# ESP32-P4 register map
Vendor: ESPRESSIF SYSTEMS (SHANGHAI) CO., LTD.; Series: ESP32 P-Series; File version: 2
CPU: RV32IMAFC r0p0, little endian, no MPU, FPU, 0 interrupt priority bits
Address unit: 32 bits
Registers are 32-bit, read-write, reset 0x0 unless marked. A register's access mark holds for its fields unless they carry their own. Offsets are from the block's base; [hi:lo] are bit positions; {n}, {i} and the like mark numbered series.

## DMA — DMA (Direct Memory Access) Controller
Base 0x50081000
0x00 ID0 ro
  [31:0] DMAC_ID
0x08 COMPVER0 ro reset 0x3230302A
  [31:0] DMAC_COMPVER
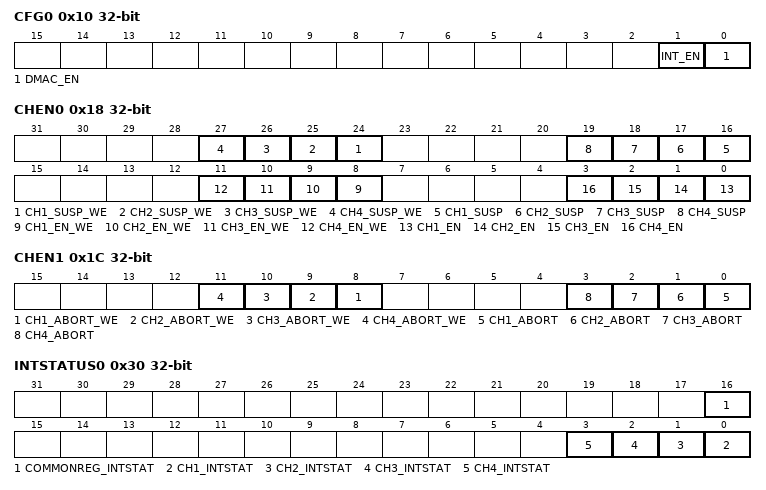
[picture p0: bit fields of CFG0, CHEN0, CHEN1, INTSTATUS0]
0x10 CFG0
  [1] INT_EN, [0] DMAC_EN
0x18 CHEN0 access per field
  [n+23] CH{n}_SUSP_WE wo (n=1..4), [n+15] CH{n}_SUSP rw (n=1..4), [n+7] CH{n}_EN_WE wo (n=1..4), [n-1] CH{n}_EN rw (n=1..4)
0x1C CHEN1 access per field
  [n+7] CH{n}_ABORT_WE wo (n=1..4), [n-1] CH{n}_ABORT rw (n=1..4)
0x30 INTSTATUS0 ro
  [16] COMMONREG_INTSTAT, [n-1] CH{n}_INTSTAT (n=1..4)
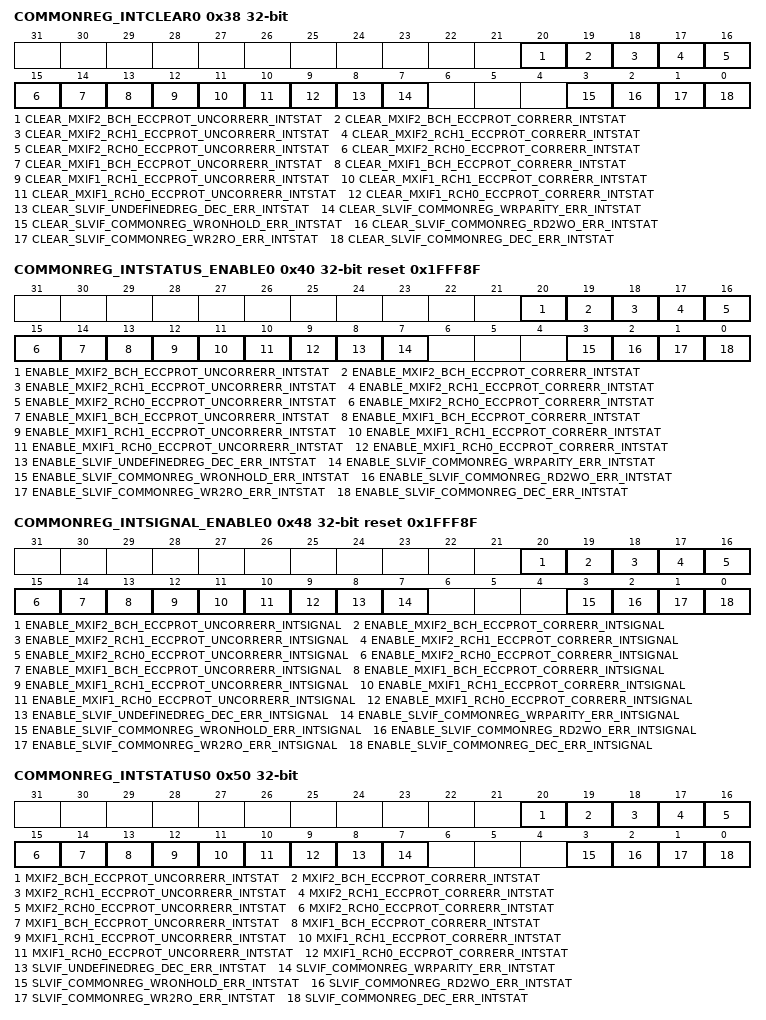
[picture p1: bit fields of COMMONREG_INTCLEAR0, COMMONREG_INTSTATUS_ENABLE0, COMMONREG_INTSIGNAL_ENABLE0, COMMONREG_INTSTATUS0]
0x38 COMMONREG_INTCLEAR0 wo
  [20] CLEAR_MXIF2_BCH_ECCPROT_UNCORRERR_INTSTAT, [19] CLEAR_MXIF2_BCH_ECCPROT_CORRERR_INTSTAT, [18] CLEAR_MXIF2_RCH1_ECCPROT_UNCORRERR_INTSTAT, [17] CLEAR_MXIF2_RCH1_ECCPROT_CORRERR_INTSTAT, [16] CLEAR_MXIF2_RCH0_ECCPROT_UNCORRERR_INTSTAT, [15] CLEAR_MXIF2_RCH0_ECCPROT_CORRERR_INTSTAT, [14] CLEAR_MXIF1_BCH_ECCPROT_UNCORRERR_INTSTAT, [13] CLEAR_MXIF1_BCH_ECCPROT_CORRERR_INTSTAT, [12] CLEAR_MXIF1_RCH1_ECCPROT_UNCORRERR_INTSTAT, [11] CLEAR_MXIF1_RCH1_ECCPROT_CORRERR_INTSTAT, [10] CLEAR_MXIF1_RCH0_ECCPROT_UNCORRERR_INTSTAT, [9] CLEAR_MXIF1_RCH0_ECCPROT_CORRERR_INTSTAT, [8] CLEAR_SLVIF_UNDEFINEDREG_DEC_ERR_INTSTAT, [7] CLEAR_SLVIF_COMMONREG_WRPARITY_ERR_INTSTAT, [3] CLEAR_SLVIF_COMMONREG_WRONHOLD_ERR_INTSTAT, [2] CLEAR_SLVIF_COMMONREG_RD2WO_ERR_INTSTAT, [1] CLEAR_SLVIF_COMMONREG_WR2RO_ERR_INTSTAT, [0] CLEAR_SLVIF_COMMONREG_DEC_ERR_INTSTAT
0x40 COMMONREG_INTSTATUS_ENABLE0 access per field reset 0x1FFF8F
  [20] ENABLE_MXIF2_BCH_ECCPROT_UNCORRERR_INTSTAT ro, [19] ENABLE_MXIF2_BCH_ECCPROT_CORRERR_INTSTAT ro, [18] ENABLE_MXIF2_RCH1_ECCPROT_UNCORRERR_INTSTAT ro, [17] ENABLE_MXIF2_RCH1_ECCPROT_CORRERR_INTSTAT ro, [16] ENABLE_MXIF2_RCH0_ECCPROT_UNCORRERR_INTSTAT ro, [15] ENABLE_MXIF2_RCH0_ECCPROT_CORRERR_INTSTAT ro, [14] ENABLE_MXIF1_BCH_ECCPROT_UNCORRERR_INTSTAT ro, [13] ENABLE_MXIF1_BCH_ECCPROT_CORRERR_INTSTAT ro, [12] ENABLE_MXIF1_RCH1_ECCPROT_UNCORRERR_INTSTAT ro, [11] ENABLE_MXIF1_RCH1_ECCPROT_CORRERR_INTSTAT ro, [10] ENABLE_MXIF1_RCH0_ECCPROT_UNCORRERR_INTSTAT ro, [9] ENABLE_MXIF1_RCH0_ECCPROT_CORRERR_INTSTAT ro, [8] ENABLE_SLVIF_UNDEFINEDREG_DEC_ERR_INTSTAT rw, [7] ENABLE_SLVIF_COMMONREG_WRPARITY_ERR_INTSTAT ro, [3] ENABLE_SLVIF_COMMONREG_WRONHOLD_ERR_INTSTAT rw, [2] ENABLE_SLVIF_COMMONREG_RD2WO_ERR_INTSTAT rw, [1] ENABLE_SLVIF_COMMONREG_WR2RO_ERR_INTSTAT rw, [0] ENABLE_SLVIF_COMMONREG_DEC_ERR_INTSTAT rw
0x48 COMMONREG_INTSIGNAL_ENABLE0 access per field reset 0x1FFF8F
  [20] ENABLE_MXIF2_BCH_ECCPROT_UNCORRERR_INTSIGNAL ro, [19] ENABLE_MXIF2_BCH_ECCPROT_CORRERR_INTSIGNAL ro, [18] ENABLE_MXIF2_RCH1_ECCPROT_UNCORRERR_INTSIGNAL ro, [17] ENABLE_MXIF2_RCH1_ECCPROT_CORRERR_INTSIGNAL ro, [16] ENABLE_MXIF2_RCH0_ECCPROT_UNCORRERR_INTSIGNAL ro, [15] ENABLE_MXIF2_RCH0_ECCPROT_CORRERR_INTSIGNAL ro, [14] ENABLE_MXIF1_BCH_ECCPROT_UNCORRERR_INTSIGNAL ro, [13] ENABLE_MXIF1_BCH_ECCPROT_CORRERR_INTSIGNAL ro, [12] ENABLE_MXIF1_RCH1_ECCPROT_UNCORRERR_INTSIGNAL ro, [11] ENABLE_MXIF1_RCH1_ECCPROT_CORRERR_INTSIGNAL ro, [10] ENABLE_MXIF1_RCH0_ECCPROT_UNCORRERR_INTSIGNAL ro, [9] ENABLE_MXIF1_RCH0_ECCPROT_CORRERR_INTSIGNAL ro, [8] ENABLE_SLVIF_UNDEFINEDREG_DEC_ERR_INTSIGNAL rw, [7] ENABLE_SLVIF_COMMONREG_WRPARITY_ERR_INTSIGNAL ro, [3] ENABLE_SLVIF_COMMONREG_WRONHOLD_ERR_INTSIGNAL rw, [2] ENABLE_SLVIF_COMMONREG_RD2WO_ERR_INTSIGNAL rw, [1] ENABLE_SLVIF_COMMONREG_WR2RO_ERR_INTSIGNAL rw, [0] ENABLE_SLVIF_COMMONREG_DEC_ERR_INTSIGNAL rw
0x50 COMMONREG_INTSTATUS0 ro
  [20] MXIF2_BCH_ECCPROT_UNCORRERR_INTSTAT, [19] MXIF2_BCH_ECCPROT_CORRERR_INTSTAT, [18] MXIF2_RCH1_ECCPROT_UNCORRERR_INTSTAT, [17] MXIF2_RCH1_ECCPROT_CORRERR_INTSTAT, [16] MXIF2_RCH0_ECCPROT_UNCORRERR_INTSTAT, [15] MXIF2_RCH0_ECCPROT_CORRERR_INTSTAT, [14] MXIF1_BCH_ECCPROT_UNCORRERR_INTSTAT, [13] MXIF1_BCH_ECCPROT_CORRERR_INTSTAT, [12] MXIF1_RCH1_ECCPROT_UNCORRERR_INTSTAT, [11] MXIF1_RCH1_ECCPROT_CORRERR_INTSTAT, [10] MXIF1_RCH0_ECCPROT_UNCORRERR_INTSTAT, [9] MXIF1_RCH0_ECCPROT_CORRERR_INTSTAT, [8] SLVIF_UNDEFINEDREG_DEC_ERR_INTSTAT, [7] SLVIF_COMMONREG_WRPARITY_ERR_INTSTAT, [3] SLVIF_COMMONREG_WRONHOLD_ERR_INTSTAT, [2] SLVIF_COMMONREG_RD2WO_ERR_INTSTAT, [1] SLVIF_COMMONREG_WR2RO_ERR_INTSTAT, [0] SLVIF_COMMONREG_DEC_ERR_INTSTAT
0x58 RESET0
  [0] DMAC_RST
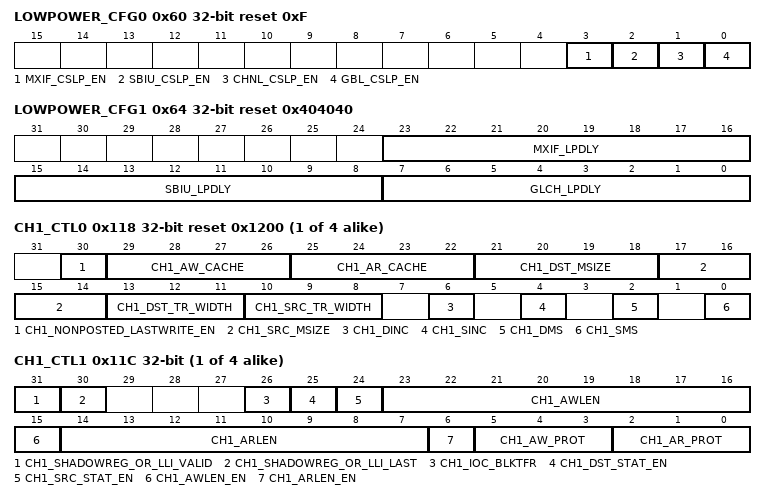
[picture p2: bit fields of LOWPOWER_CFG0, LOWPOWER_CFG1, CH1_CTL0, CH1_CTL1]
0x60 LOWPOWER_CFG0 reset 0xF
  [3] MXIF_CSLP_EN, [2] SBIU_CSLP_EN, [1] CHNL_CSLP_EN, [0] GBL_CSLP_EN
0x64 LOWPOWER_CFG1 reset 0x404040
  [23:16] MXIF_LPDLY, [15:8] SBIU_LPDLY, [7:0] GLCH_LPDLY
{0x0+0x100*i} CH{i}_SAR0 (i=1..4)
{0x4+0x100*i} CH{i}_SAR1 (i=1..4)
{0x8+0x100*i} CH{i}_DAR0 (i=1..4)
{0xC+0x100*i} CH{i}_DAR1 (i=1..4)
{0x10+0x100*i} CH{i}_BLOCK_TS0 (i=1..4)
  [21:0] CH{i}_BLOCK_TS
{0x18+0x100*i} CH{i}_CTL0 reset 0x1200 (i=1..4)
  [30] CH{i}_NONPOSTED_LASTWRITE_EN, [29:26] CH{i}_AW_CACHE, [25:22] CH{i}_AR_CACHE, [21:18] CH{i}_DST_MSIZE, [17:14] CH{i}_SRC_MSIZE, [13:11] CH{i}_DST_TR_WIDTH, [10:8] CH{i}_SRC_TR_WIDTH, [6] CH{i}_DINC, [4] CH{i}_SINC, [2] CH{i}_DMS, [0] CH{i}_SMS
{0x1C+0x100*i} CH{i}_CTL1 (i=1..4)
  [31] CH{i}_SHADOWREG_OR_LLI_VALID, [30] CH{i}_SHADOWREG_OR_LLI_LAST, [26] CH{i}_IOC_BLKTFR, [25] CH{i}_DST_STAT_EN, [24] CH{i}_SRC_STAT_EN, [23:16] CH{i}_AWLEN, [15] CH{i}_AWLEN_EN, [14:7] CH{i}_ARLEN, [6] CH{i}_ARLEN_EN, [5:3] CH{i}_AW_PROT, [2:0] CH{i}_AR_PROT
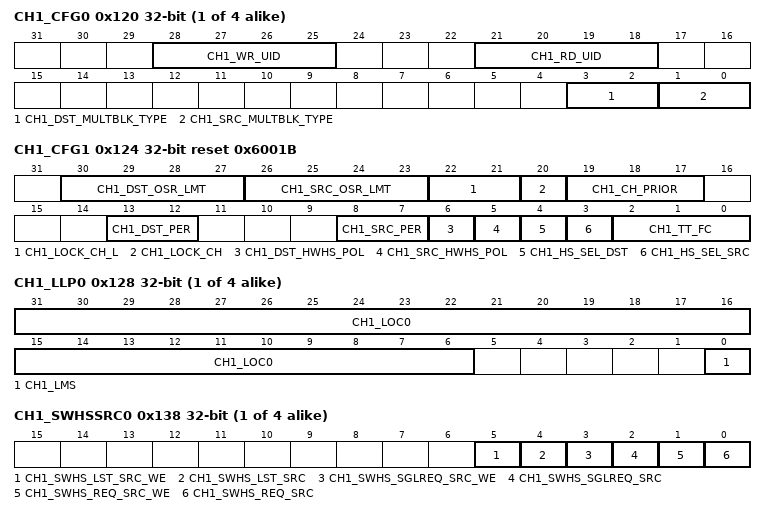
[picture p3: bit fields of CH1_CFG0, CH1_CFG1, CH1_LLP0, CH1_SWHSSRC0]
{0x20+0x100*i} CH{i}_CFG0 access per field (i=1..4)
  [28:25] CH{i}_WR_UID ro, [21:18] CH{i}_RD_UID ro, [3:2] CH{i}_DST_MULTBLK_TYPE rw, [1:0] CH{i}_SRC_MULTBLK_TYPE rw
0x124 CH1_CFG1 access per field reset 0x6001B
  [30:27] CH1_DST_OSR_LMT rw, [26:23] CH1_SRC_OSR_LMT rw, [22:21] CH1_LOCK_CH_L ro, [20] CH1_LOCK_CH ro, [19:17] CH1_CH_PRIOR rw, [13:12] CH1_DST_PER rw, [8:7] CH1_SRC_PER rw, [6] CH1_DST_HWHS_POL ro, [5] CH1_SRC_HWHS_POL ro, [4] CH1_HS_SEL_DST rw, [3] CH1_HS_SEL_SRC rw, [2:0] CH1_TT_FC rw
{0x28+0x100*i} CH{i}_LLP0 (i=1..4)
  [31:6] CH{i}_LOC0, [0] CH{i}_LMS
{0x2C+0x100*i} CH{i}_LLP1 (i=1..4)
  [31:0] CH{i}_LOC1
{0x30+0x100*i} CH{i}_STATUS0 ro (i=1..4)
  [21:0] CH{i}_CMPLTD_BLK_TFR_SIZE
{0x34+0x100*i} CH{i}_STATUS1 ro (i=1..4)
  [14:0] CH{i}_DATA_LEFT_IN_FIFO
{0x38+0x100*i} CH{i}_SWHSSRC0 access per field (i=1..4)
  [5] CH{i}_SWHS_LST_SRC_WE wo, [4] CH{i}_SWHS_LST_SRC rw, [3] CH{i}_SWHS_SGLREQ_SRC_WE wo, [2] CH{i}_SWHS_SGLREQ_SRC rw, [1] CH{i}_SWHS_REQ_SRC_WE wo, [0] CH{i}_SWHS_REQ_SRC rw
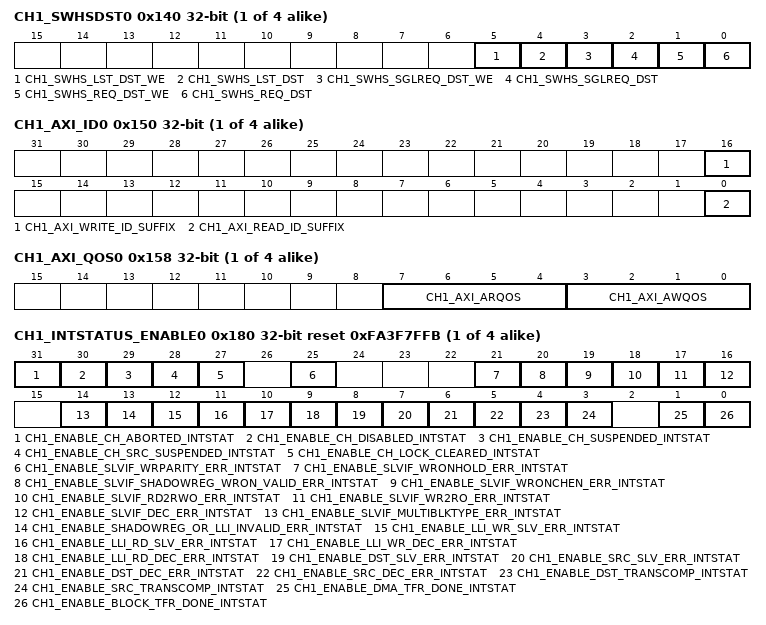
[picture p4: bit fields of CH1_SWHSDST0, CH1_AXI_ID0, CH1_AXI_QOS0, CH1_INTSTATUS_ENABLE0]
{0x40+0x100*i} CH{i}_SWHSDST0 access per field (i=1..4)
  [5] CH{i}_SWHS_LST_DST_WE wo, [4] CH{i}_SWHS_LST_DST rw, [3] CH{i}_SWHS_SGLREQ_DST_WE wo, [2] CH{i}_SWHS_SGLREQ_DST rw, [1] CH{i}_SWHS_REQ_DST_WE wo, [0] CH{i}_SWHS_REQ_DST rw
{0x48+0x100*i} CH{i}_BLK_TFR_RESUMEREQ0 wo (i=1..4)
  [0] CH{i}_BLK_TFR_RESUMEREQ
{0x50+0x100*i} CH{i}_AXI_ID0 (i=1..4)
  [16] CH{i}_AXI_WRITE_ID_SUFFIX, [0] CH{i}_AXI_READ_ID_SUFFIX
{0x58+0x100*i} CH{i}_AXI_QOS0 (i=1..4)
  [7:4] CH{i}_AXI_ARQOS, [3:0] CH{i}_AXI_AWQOS
{0x60+0x100*i} CH{i}_SSTAT0 ro (i=1..4)
  [31:0] CH{i}_SSTAT
{0x68+0x100*i} CH{i}_DSTAT0 ro (i=1..4)
  [31:0] CH{i}_DSTAT
{0x70+0x100*i} CH{i}_SSTATAR0 (i=1..4)
{0x74+0x100*i} CH{i}_SSTATAR1 (i=1..4)
{0x78+0x100*i} CH{i}_DSTATAR0 (i=1..4)
{0x7C+0x100*i} CH{i}_DSTATAR1 (i=1..4)
{0x80+0x100*i} CH{i}_INTSTATUS_ENABLE0 access per field reset 0xFA3F7FFB (i=1..4)
  [31] CH{i}_ENABLE_CH_ABORTED_INTSTAT rw, [30] CH{i}_ENABLE_CH_DISABLED_INTSTAT rw, [29] CH{i}_ENABLE_CH_SUSPENDED_INTSTAT rw, [28] CH{i}_ENABLE_CH_SRC_SUSPENDED_INTSTAT rw, [27] CH{i}_ENABLE_CH_LOCK_CLEARED_INTSTAT rw, [25] CH{i}_ENABLE_SLVIF_WRPARITY_ERR_INTSTAT ro, [21] CH{i}_ENABLE_SLVIF_WRONHOLD_ERR_INTSTAT rw, [20] CH{i}_ENABLE_SLVIF_SHADOWREG_WRON_VALID_ERR_INTSTAT rw, [19] CH{i}_ENABLE_SLVIF_WRONCHEN_ERR_INTSTAT rw, [18] CH{i}_ENABLE_SLVIF_RD2RWO_ERR_INTSTAT rw, [17] CH{i}_ENABLE_SLVIF_WR2RO_ERR_INTSTAT rw, [16] CH{i}_ENABLE_SLVIF_DEC_ERR_INTSTAT rw, [14] CH{i}_ENABLE_SLVIF_MULTIBLKTYPE_ERR_INTSTAT rw, [13] CH{i}_ENABLE_SHADOWREG_OR_LLI_INVALID_ERR_INTSTAT rw, [12] CH{i}_ENABLE_LLI_WR_SLV_ERR_INTSTAT rw, [11] CH{i}_ENABLE_LLI_RD_SLV_ERR_INTSTAT rw, [10] CH{i}_ENABLE_LLI_WR_DEC_ERR_INTSTAT rw, [9] CH{i}_ENABLE_LLI_RD_DEC_ERR_INTSTAT rw, [8] CH{i}_ENABLE_DST_SLV_ERR_INTSTAT rw, [7] CH{i}_ENABLE_SRC_SLV_ERR_INTSTAT rw, [6] CH{i}_ENABLE_DST_DEC_ERR_INTSTAT rw, [5] CH{i}_ENABLE_SRC_DEC_ERR_INTSTAT rw, [4] CH{i}_ENABLE_DST_TRANSCOMP_INTSTAT rw, [3] CH{i}_ENABLE_SRC_TRANSCOMP_INTSTAT rw, [1] CH{i}_ENABLE_DMA_TFR_DONE_INTSTAT rw, [0] CH{i}_ENABLE_BLOCK_TFR_DONE_INTSTAT rw
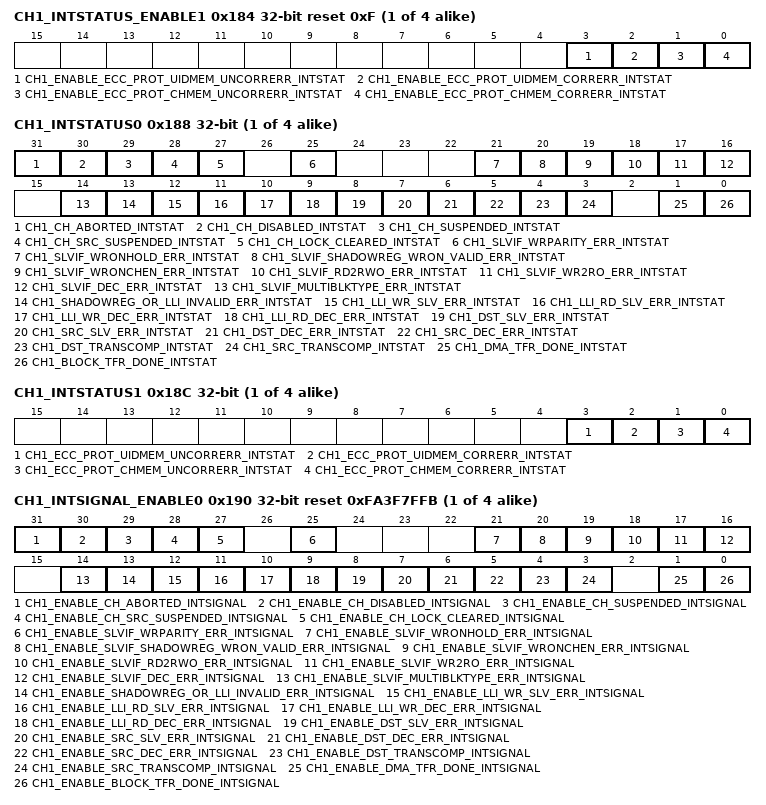
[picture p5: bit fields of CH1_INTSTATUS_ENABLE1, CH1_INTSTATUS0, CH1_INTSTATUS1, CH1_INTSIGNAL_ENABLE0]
{0x84+0x100*i} CH{i}_INTSTATUS_ENABLE1 ro reset 0xF (i=1..4)
  [3] CH{i}_ENABLE_ECC_PROT_UIDMEM_UNCORRERR_INTSTAT, [2] CH{i}_ENABLE_ECC_PROT_UIDMEM_CORRERR_INTSTAT, [1] CH{i}_ENABLE_ECC_PROT_CHMEM_UNCORRERR_INTSTAT, [0] CH{i}_ENABLE_ECC_PROT_CHMEM_CORRERR_INTSTAT
{0x88+0x100*i} CH{i}_INTSTATUS0 ro (i=1..4)
  [31] CH{i}_CH_ABORTED_INTSTAT, [30] CH{i}_CH_DISABLED_INTSTAT, [29] CH{i}_CH_SUSPENDED_INTSTAT, [28] CH{i}_CH_SRC_SUSPENDED_INTSTAT, [27] CH{i}_CH_LOCK_CLEARED_INTSTAT, [25] CH{i}_SLVIF_WRPARITY_ERR_INTSTAT, [21] CH{i}_SLVIF_WRONHOLD_ERR_INTSTAT, [20] CH{i}_SLVIF_SHADOWREG_WRON_VALID_ERR_INTSTAT, [19] CH{i}_SLVIF_WRONCHEN_ERR_INTSTAT, [18] CH{i}_SLVIF_RD2RWO_ERR_INTSTAT, [17] CH{i}_SLVIF_WR2RO_ERR_INTSTAT, [16] CH{i}_SLVIF_DEC_ERR_INTSTAT, [14] CH{i}_SLVIF_MULTIBLKTYPE_ERR_INTSTAT, [13] CH{i}_SHADOWREG_OR_LLI_INVALID_ERR_INTSTAT, [12] CH{i}_LLI_WR_SLV_ERR_INTSTAT, [11] CH{i}_LLI_RD_SLV_ERR_INTSTAT, [10] CH{i}_LLI_WR_DEC_ERR_INTSTAT, [9] CH{i}_LLI_RD_DEC_ERR_INTSTAT, [8] CH{i}_DST_SLV_ERR_INTSTAT, [7] CH{i}_SRC_SLV_ERR_INTSTAT, [6] CH{i}_DST_DEC_ERR_INTSTAT, [5] CH{i}_SRC_DEC_ERR_INTSTAT, [4] CH{i}_DST_TRANSCOMP_INTSTAT, [3] CH{i}_SRC_TRANSCOMP_INTSTAT, [1] CH{i}_DMA_TFR_DONE_INTSTAT, [0] CH{i}_BLOCK_TFR_DONE_INTSTAT
{0x8C+0x100*i} CH{i}_INTSTATUS1 ro (i=1..4)
  [3] CH{i}_ECC_PROT_UIDMEM_UNCORRERR_INTSTAT, [2] CH{i}_ECC_PROT_UIDMEM_CORRERR_INTSTAT, [1] CH{i}_ECC_PROT_CHMEM_UNCORRERR_INTSTAT, [0] CH{i}_ECC_PROT_CHMEM_CORRERR_INTSTAT
{0x90+0x100*i} CH{i}_INTSIGNAL_ENABLE0 access per field reset 0xFA3F7FFB (i=1..4)
  [31] CH{i}_ENABLE_CH_ABORTED_INTSIGNAL rw, [30] CH{i}_ENABLE_CH_DISABLED_INTSIGNAL rw, [29] CH{i}_ENABLE_CH_SUSPENDED_INTSIGNAL rw, [28] CH{i}_ENABLE_CH_SRC_SUSPENDED_INTSIGNAL rw, [27] CH{i}_ENABLE_CH_LOCK_CLEARED_INTSIGNAL rw, [25] CH{i}_ENABLE_SLVIF_WRPARITY_ERR_INTSIGNAL ro, [21] CH{i}_ENABLE_SLVIF_WRONHOLD_ERR_INTSIGNAL rw, [20] CH{i}_ENABLE_SLVIF_SHADOWREG_WRON_VALID_ERR_INTSIGNAL rw, [19] CH{i}_ENABLE_SLVIF_WRONCHEN_ERR_INTSIGNAL rw, [18] CH{i}_ENABLE_SLVIF_RD2RWO_ERR_INTSIGNAL rw, [17] CH{i}_ENABLE_SLVIF_WR2RO_ERR_INTSIGNAL rw, [16] CH{i}_ENABLE_SLVIF_DEC_ERR_INTSIGNAL rw, [14] CH{i}_ENABLE_SLVIF_MULTIBLKTYPE_ERR_INTSIGNAL rw, [13] CH{i}_ENABLE_SHADOWREG_OR_LLI_INVALID_ERR_INTSIGNAL rw, [12] CH{i}_ENABLE_LLI_WR_SLV_ERR_INTSIGNAL rw, [11] CH{i}_ENABLE_LLI_RD_SLV_ERR_INTSIGNAL rw, [10] CH{i}_ENABLE_LLI_WR_DEC_ERR_INTSIGNAL rw, [9] CH{i}_ENABLE_LLI_RD_DEC_ERR_INTSIGNAL rw, [8] CH{i}_ENABLE_DST_SLV_ERR_INTSIGNAL rw, [7] CH{i}_ENABLE_SRC_SLV_ERR_INTSIGNAL rw, [6] CH{i}_ENABLE_DST_DEC_ERR_INTSIGNAL rw, [5] CH{i}_ENABLE_SRC_DEC_ERR_INTSIGNAL rw, [4] CH{i}_ENABLE_DST_TRANSCOMP_INTSIGNAL rw, [3] CH{i}_ENABLE_SRC_TRANSCOMP_INTSIGNAL rw, [1] CH{i}_ENABLE_DMA_TFR_DONE_INTSIGNAL rw, [0] CH{i}_ENABLE_BLOCK_TFR_DONE_INTSIGNAL rw
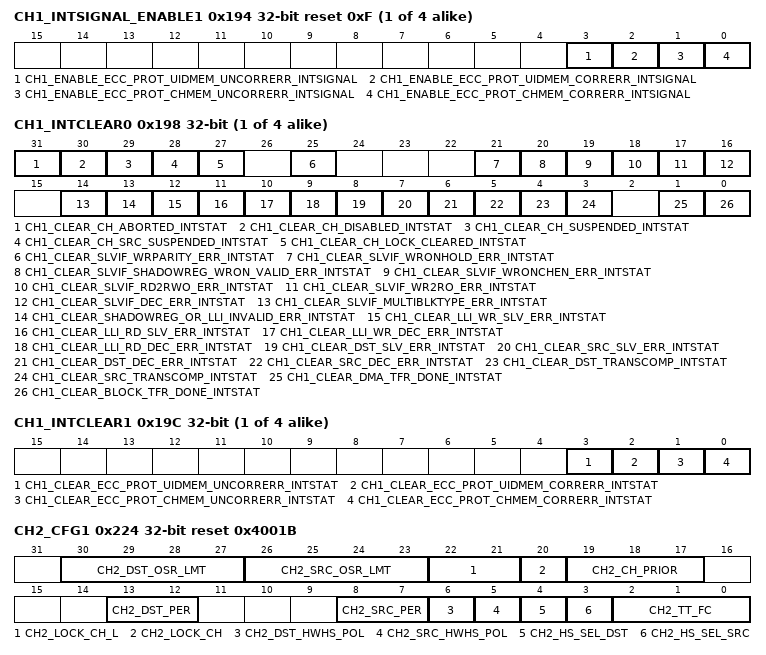
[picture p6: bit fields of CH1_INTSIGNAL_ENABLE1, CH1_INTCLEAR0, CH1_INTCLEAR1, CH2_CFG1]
{0x94+0x100*i} CH{i}_INTSIGNAL_ENABLE1 ro reset 0xF (i=1..4)
  [3] CH{i}_ENABLE_ECC_PROT_UIDMEM_UNCORRERR_INTSIGNAL, [2] CH{i}_ENABLE_ECC_PROT_UIDMEM_CORRERR_INTSIGNAL, [1] CH{i}_ENABLE_ECC_PROT_CHMEM_UNCORRERR_INTSIGNAL, [0] CH{i}_ENABLE_ECC_PROT_CHMEM_CORRERR_INTSIGNAL
{0x98+0x100*i} CH{i}_INTCLEAR0 wo (i=1..4)
  [31] CH{i}_CLEAR_CH_ABORTED_INTSTAT, [30] CH{i}_CLEAR_CH_DISABLED_INTSTAT, [29] CH{i}_CLEAR_CH_SUSPENDED_INTSTAT, [28] CH{i}_CLEAR_CH_SRC_SUSPENDED_INTSTAT, [27] CH{i}_CLEAR_CH_LOCK_CLEARED_INTSTAT, [25] CH{i}_CLEAR_SLVIF_WRPARITY_ERR_INTSTAT, [21] CH{i}_CLEAR_SLVIF_WRONHOLD_ERR_INTSTAT, [20] CH{i}_CLEAR_SLVIF_SHADOWREG_WRON_VALID_ERR_INTSTAT, [19] CH{i}_CLEAR_SLVIF_WRONCHEN_ERR_INTSTAT, [18] CH{i}_CLEAR_SLVIF_RD2RWO_ERR_INTSTAT, [17] CH{i}_CLEAR_SLVIF_WR2RO_ERR_INTSTAT, [16] CH{i}_CLEAR_SLVIF_DEC_ERR_INTSTAT, [14] CH{i}_CLEAR_SLVIF_MULTIBLKTYPE_ERR_INTSTAT, [13] CH{i}_CLEAR_SHADOWREG_OR_LLI_INVALID_ERR_INTSTAT, [12] CH{i}_CLEAR_LLI_WR_SLV_ERR_INTSTAT, [11] CH{i}_CLEAR_LLI_RD_SLV_ERR_INTSTAT, [10] CH{i}_CLEAR_LLI_WR_DEC_ERR_INTSTAT, [9] CH{i}_CLEAR_LLI_RD_DEC_ERR_INTSTAT, [8] CH{i}_CLEAR_DST_SLV_ERR_INTSTAT, [7] CH{i}_CLEAR_SRC_SLV_ERR_INTSTAT, [6] CH{i}_CLEAR_DST_DEC_ERR_INTSTAT, [5] CH{i}_CLEAR_SRC_DEC_ERR_INTSTAT, [4] CH{i}_CLEAR_DST_TRANSCOMP_INTSTAT, [3] CH{i}_CLEAR_SRC_TRANSCOMP_INTSTAT, [1] CH{i}_CLEAR_DMA_TFR_DONE_INTSTAT, [0] CH{i}_CLEAR_BLOCK_TFR_DONE_INTSTAT
{0x9C+0x100*i} CH{i}_INTCLEAR1 wo (i=1..4)
  [3] CH{i}_CLEAR_ECC_PROT_UIDMEM_UNCORRERR_INTSTAT, [2] CH{i}_CLEAR_ECC_PROT_UIDMEM_CORRERR_INTSTAT, [1] CH{i}_CLEAR_ECC_PROT_CHMEM_UNCORRERR_INTSTAT, [0] CH{i}_CLEAR_ECC_PROT_CHMEM_CORRERR_INTSTAT
0x224 CH2_CFG1 access per field reset 0x4001B
  [30:27] CH2_DST_OSR_LMT rw, [26:23] CH2_SRC_OSR_LMT rw, [22:21] CH2_LOCK_CH_L ro, [20] CH2_LOCK_CH ro, [19:17] CH2_CH_PRIOR rw, [13:12] CH2_DST_PER rw, [8:7] CH2_SRC_PER rw, [6] CH2_DST_HWHS_POL ro, [5] CH2_SRC_HWHS_POL ro, [4] CH2_HS_SEL_DST rw, [3] CH2_HS_SEL_SRC rw, [2:0] CH2_TT_FC rw
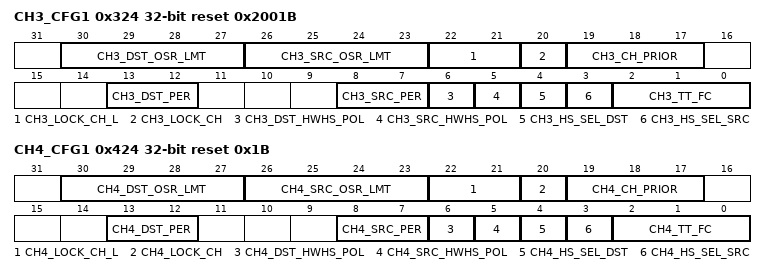
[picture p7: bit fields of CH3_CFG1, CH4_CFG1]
0x324 CH3_CFG1 access per field reset 0x2001B
  [30:27] CH3_DST_OSR_LMT rw, [26:23] CH3_SRC_OSR_LMT rw, [22:21] CH3_LOCK_CH_L ro, [20] CH3_LOCK_CH ro, [19:17] CH3_CH_PRIOR rw, [13:12] CH3_DST_PER rw, [8:7] CH3_SRC_PER rw, [6] CH3_DST_HWHS_POL ro, [5] CH3_SRC_HWHS_POL ro, [4] CH3_HS_SEL_DST rw, [3] CH3_HS_SEL_SRC rw, [2:0] CH3_TT_FC rw
0x424 CH4_CFG1 access per field reset 0x1B
  [30:27] CH4_DST_OSR_LMT rw, [26:23] CH4_SRC_OSR_LMT rw, [22:21] CH4_LOCK_CH_L ro, [20] CH4_LOCK_CH ro, [19:17] CH4_CH_PRIOR rw, [13:12] CH4_DST_PER rw, [8:7] CH4_SRC_PER rw, [6] CH4_DST_HWHS_POL ro, [5] CH4_SRC_HWHS_POL ro, [4] CH4_HS_SEL_DST rw, [3] CH4_HS_SEL_SRC rw, [2:0] CH4_TT_FC rw
